# PIC32MK1024GPE064 device description
Architecture: MIPS; Family: PIC32MK; Series: PIC32MK
Registers are 32-bit, read-write, no defined reset value unless marked. A register's access mark holds for its fields unless they carry their own. Offsets are from the block's base; [hi:lo] are bit positions; {n}, {i} and the like mark numbered series.

## DMT
Instances: DMT 0x1f800e00 in periph_pb1_std
0x00 DMTCON — Deadman Timer Control Register
  [15] ON — Deadman Timer Module Enable bit
    1=Deadman Timer module is enabled; 0=Deadman Timer module is disabled
0x10 DMTPRECLR — Deadman Timer Preclear Register
  [15:8] STEP1 — Preclear Enable bits
    64=Enables the Deadman Timer Preclear (Step 1)
0x20 DMTCLR — Deadman Timer Clear Register
  [7:0] STEP2 — Clear Timer bits
    8=Clears STEP1
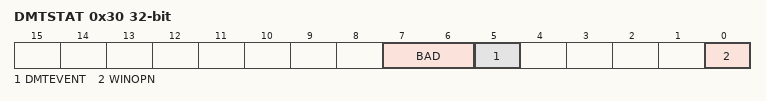
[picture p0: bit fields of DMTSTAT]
0x30 DMTSTAT ro — Deadman Timer Status Register
  [7:6] BAD
  [5] DMTEVENT — Deadman Timer Event bit
    1=Deadman timer event was detected (counter expired or bad STEP1 or STEP2 value was entered prior to counter increment); 0=Deadman timer even was not detected
  [0] WINOPN — Deadman Timer Clear Window bit
    1=Deadman timer clear window is open; 0=Deadman timer clear window is not open
0x40 DMTCNT ro — Deadman Timer Count Register
  [31:0] COUNTER
0x60 DMTPSCNT ro — Post Status Configure DMT Count Status Register
  [31:0] PSCNT
0x70 DMTPSINTV ro — Post Status Configure DMT Interval Status Register
  [31:0] PSINTV
Value list DMTSTAT__BAD2: 64=Incorrect STEP2 value was detected; 0=Incorrect STEP2 value was not detected
Value list DMTSTAT__BAD1: 128=Incorrect STEP1 value or out of sequence write to STEP2 was detected; 0=Incorrect STEP1 value was not detected

## DSCTRL
Instances: DSCTRL 0x1f8c0200 in periph_pb6_std
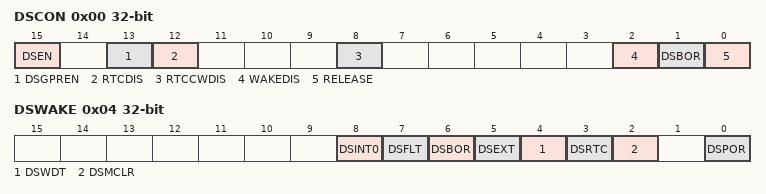
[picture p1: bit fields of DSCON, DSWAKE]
0x00 DSCON
  [15] DSEN, [13] DSGPREN, [12] RTCDIS, [8] RTCCWDIS, [2] WAKEDIS, [1] DSBOR, [0] RELEASE
0x04 DSWAKE
  [8] DSINT0, [7] DSFLT, [6] DSBOR, [5] DSEXT, [4] DSWDT, [3] DSRTC, [2] DSMCLR, [0] DSPOR
0x08 DSGPR0
  [31:0] DSGPR
{0xC+4i} DSGPR{i} (i=1..32)
  [31:0] DSGPR

## EEPROM
Instances: EEPROM 0x1f829000 in periph_pb2_std
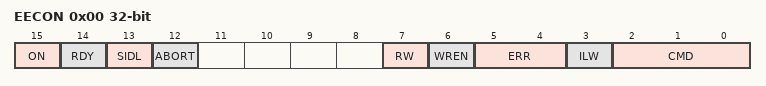
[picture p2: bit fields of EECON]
0x00 EECON — EEPROM CONTROL REGISTER
  [15] ON — Data EEPROM Power Control bit
    1=Data EEPROM is enabled; 0=Data EEPROM is disabled
  [14] RDY — Data EEPROM Ready bit
    1=Data EEPROM is ready for access; 0=Data EEPROM is not ready for access
  [13] SIDL — Stop in Idle Mode bit
    1=Discontinue operation when CPU enters in Idle mode; 0=Continue operation in Idle mode
  [12] ABORT — Data EEPROM Abort Operation Control bit
    1=Set by software to abort the on-going write command as soon as possible; 0=Data EEPROM panel is ready/Normal operation
  [7] RW — Start Command Execution Control bit
    1=(when WREN is 1)Start memory word program or erase command / (when WREN is 0)Cleared by hardware to indicate read operation has completed; 0=(when WREN is 1)Cleared by hardware to indicate program or erase operation has completed / (when WREN is 0)Cleared by hardware to indicate read operation has completed
  [6] WREN — Data EEPROM Write Enable Control bit
    1=Enables program or erase operations; 0=Disables program or erase of memory elements, and enables read operations
  [5:4] ERR — Data EEPROM Sequence Error Status bits
    3=A BOR event has occurred; 2=An attempted execution of a read or write operation with an invalid write OR command with a misaligned address (EEADDR(1:0) not 00); 1=A Bulk or Page Erase or a Word Program verify error has occurred; 0=No error condition
  [3] ILW — Data EEPROM Imminent Long Write Status bit
    1=The next write to the EEPROM address (held in the EEADDR register) will require more time (approx 20 ms) than usual; 0=The next write to the EEPROM address (held in the EEADDR register) will be a normal write cycle
  [2:0] CMD — Data EEPROM Command Selection bits
    4=Configuration register Write command (WREN bit must be set); 3=Data EEPROM memory Bulk Erase command (WREN bit must be set); 2=Data EEPROM memory Page Erase command (WREN bit must be set); 1=Word Write command (WREN bit must be set); 0=Word Read command (WREN bit must be clear)
0x10 EEKEY wo — EEPROM KEY REGISTER
  [15:0] EEKEY — Data EEPROM Key bits
0x20 EEADDR — EEPROM ADDRESS REGISTER
  [15:0] EEADR — Data EEPROM Address bits
0x30 EEDATA — EEPROM DATA REGISTER
  [31:0] EEDATA — Data EEPROM Data bits

## Notices in the file
Copyright (c) 2017 Microchip Technology Inc.
SPDX-License-Identifier: Apache-2.0
Licensed under the Apache License, Version 2.0 (the "License");
you may not use this file except in compliance with the License.
You may obtain a copy of the License at
http://www.apache.org/licenses/LICENSE-2.0
Unless required by applicable law or agreed to in writing, software
distributed under the License is distributed on an "AS IS" BASIS,
WITHOUT WARRANTIES OR CONDITIONS OF ANY KIND, either express or implied.
See the License for the specific language governing permissions and
limitations under the License.
